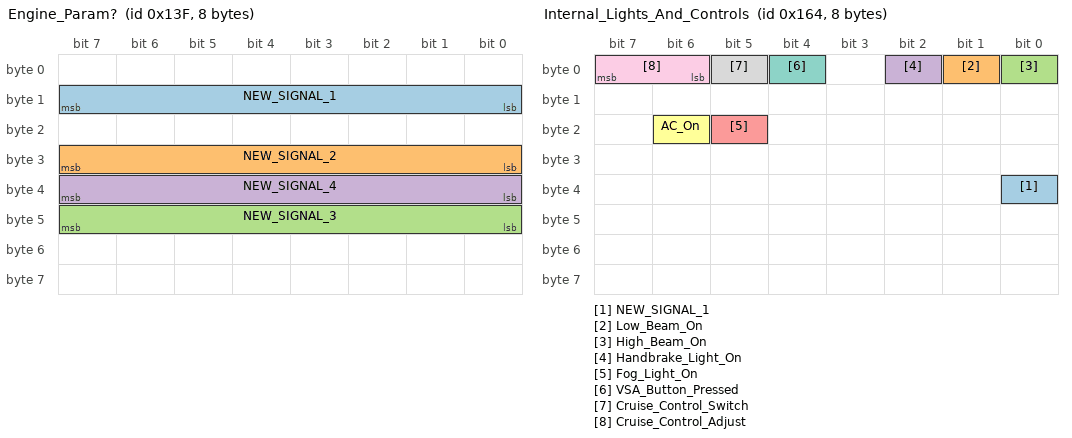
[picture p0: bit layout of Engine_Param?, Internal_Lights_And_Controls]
VERSION ""

NS_ :

BS_:

BU_: XXX

BO_ 151 Accelerometers: 8 XXX
 SG_ NEW_SIGNAL_2 : 6|24@0+ (1,0) [0|65535] "" XXX
 SG_ Accelerometer_Roll : 23|16@0+ (1,0) [0|255] "" XXX

BO_ 310 Throttle: 8 XXX
 SG_ Throttle : 31|16@0+ (1,0) [0|65535] "" XXX

BO_ 57 NEW_MSG_1: 8 XXX
 SG_ NEW_SIGNAL_1 : 15|8@0+ (1,0) [0|255] "" XXX

BO_ 319 Engine_Param?: 8 XXX
 SG_ NEW_SIGNAL_1 : 15|8@0+ (1,0) [0|7] "" XXX
 SG_ NEW_SIGNAL_2 : 31|8@0+ (1,0) [0|255] "" XXX
 SG_ NEW_SIGNAL_3 : 47|8@0+ (1,0) [0|255] "" XXX
 SG_ NEW_SIGNAL_4 : 39|8@0+ (1,0) [0|255] "" XXX

BO_ 344 NEW_MSG_2: 8 XXX

BO_ 356 Internal_Lights_And_Controls: 8 XXX
 SG_ NEW_SIGNAL_1 : 32|1@1+ (1,0) [0|3] "" XXX
 SG_ Low_Beam_On : 1|1@1+ (1,0) [0|3] "" XXX
 SG_ High_Beam_On : 0|1@1+ (1,0) [0|3] "" XXX
 SG_ Handbrake_Light_On : 2|1@1+ (1,0) [0|3] "" XXX
 SG_ Fog_Light_On : 21|1@0+ (1,0) [0|3] "" XXX
 SG_ AC_On : 22|1@0+ (1,0) [0|3] "" XXX
 SG_ VSA_Button_Pressed : 4|1@0+ (1,0) [0|3] "" XXX
 SG_ Cruise_Control_Switch : 5|1@0+ (1,0) [0|3] "" XXX
 SG_ Cruise_Control_Adjust : 7|2@0+ (1,0) [0|3] "" XXX

BO_ 380 Powertrain: 8 XXX
 SG_ Engine_RPM : 23|16@0+ (1,0) [0|255] "" XXX
 SG_ Brakes_Applied : 32|1@1+ (1,0) [0|3] "" XXX

BO_ 398 NEW_MSG_3: 8 XXX
 SG_ Steering_Torque : 15|8@0+ (1,0) [0|255] "" XXX
 SG_ NEW_SIGNAL_2 : 16|2@1+ (1,0) [0|3] "" XXX

BO_ 401 Powertrain?: 8 XXX
 SG_ In_Neutral : 51|1@0+ (1,0) [0|255] "" XXX

BO_ 323 NEW_MSG_4: 8 XXX
 SG_ NEW_SIGNAL_1 : 31|8@0+ (1,0) [0|255] "" XXX

BO_ 358 NEW_MSG_5: 8 XXX
 SG_ NEW_SIGNAL_1 : 31|8@0+ (1,0) [0|255] "" XXX

BO_ 476 NEW_MSG_6: 8 XXX
 SG_ NEW_SIGNAL_1 : 31|8@0+ (1,0) [0|255] "" XXX
 SG_ NEW_SIGNAL_2 : 23|8@0+ (1,0) [0|255] "" XXX
